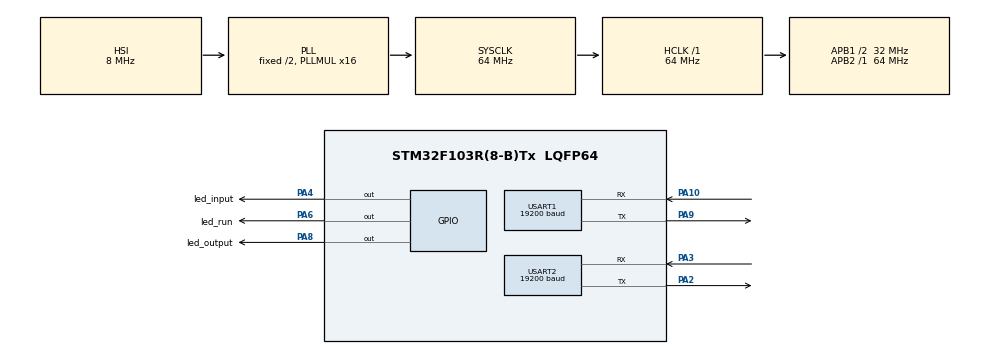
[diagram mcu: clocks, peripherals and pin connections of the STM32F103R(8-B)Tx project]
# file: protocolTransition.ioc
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Dma.Request0=USART1_RX
Dma.Request1=USART1_TX
Dma.Request2=USART2_RX
Dma.Request3=USART2_TX
Dma.USART1_RX.0.Direction=DMA_PERIPH_TO_MEMORY
Dma.USART1_RX.0.Instance=DMA1_Channel5
Dma.USART1_RX.0.MemDataAlignment=DMA_MDATAALIGN_BYTE
Dma.USART1_RX.0.MemInc=DMA_MINC_ENABLE
Dma.USART1_RX.0.Mode=DMA_NORMAL
Dma.USART1_RX.0.PeriphDataAlignment=DMA_PDATAALIGN_BYTE
Dma.USART1_RX.0.PeriphInc=DMA_PINC_DISABLE
Dma.USART1_RX.0.Priority=DMA_PRIORITY_LOW
Dma.USART1_TX.1.Direction=DMA_MEMORY_TO_PERIPH
Dma.USART1_TX.1.Instance=DMA1_Channel4
Dma.USART1_TX.1.MemDataAlignment=DMA_MDATAALIGN_BYTE
Dma.USART1_TX.1.MemInc=DMA_MINC_ENABLE
Dma.USART1_TX.1.Mode=DMA_NORMAL
Dma.USART1_TX.1.PeriphDataAlignment=DMA_PDATAALIGN_BYTE
Dma.USART1_TX.1.PeriphInc=DMA_PINC_DISABLE
Dma.USART1_TX.1.Priority=DMA_PRIORITY_LOW
Dma.USART2_RX.2.Direction=DMA_PERIPH_TO_MEMORY
Dma.USART2_RX.2.Instance=DMA1_Channel6
Dma.USART2_RX.2.MemDataAlignment=DMA_MDATAALIGN_BYTE
Dma.USART2_RX.2.MemInc=DMA_MINC_ENABLE
Dma.USART2_RX.2.Mode=DMA_NORMAL
Dma.USART2_RX.2.PeriphDataAlignment=DMA_PDATAALIGN_BYTE
Dma.USART2_RX.2.PeriphInc=DMA_PINC_DISABLE
Dma.USART2_RX.2.Priority=DMA_PRIORITY_LOW
Dma.USART2_TX.3.Direction=DMA_MEMORY_TO_PERIPH
Dma.USART2_TX.3.Instance=DMA1_Channel7
Dma.USART2_TX.3.MemDataAlignment=DMA_MDATAALIGN_BYTE
Dma.USART2_TX.3.MemInc=DMA_MINC_ENABLE
Dma.USART2_TX.3.Mode=DMA_NORMAL
Dma.USART2_TX.3.PeriphDataAlignment=DMA_PDATAALIGN_BYTE
Dma.USART2_TX.3.PeriphInc=DMA_PINC_DISABLE
Dma.USART2_TX.3.Priority=DMA_PRIORITY_LOW
Mcu.Family=STM32F1
Mcu.Name=STM32F103R(8-B)Tx
Mcu.Package=LQFP64
NVIC.DMA1_Channel4_IRQn=true\:0\:0\:false\:false\:true\:false
NVIC.DMA1_Channel5_IRQn=true\:0\:0\:false\:false\:true\:false
NVIC.DMA1_Channel6_IRQn=true\:0\:0\:false\:false\:true\:false
NVIC.DMA1_Channel7_IRQn=true\:0\:0\:false\:false\:true\:false
NVIC.PriorityGroup=NVIC_PRIORITYGROUP_4
NVIC.TIM3_IRQn=true\:0\:0\:false\:false\:true\:true
NVIC.USART1_IRQn=true\:0\:0\:false\:false\:true\:true
NVIC.USART2_IRQn=true\:0\:0\:false\:false\:true\:true
PA10.Mode=Asynchronous
PA10.Signal=USART1_RX
PA13.Mode=Serial_Wire
PA13.Signal=SYS_JTMS-SWDIO
PA14.Mode=Serial_Wire
PA14.Signal=SYS_JTCK-SWCLK
PA2.Mode=Asynchronous
PA2.Signal=USART2_TX
PA3.Mode=Asynchronous
PA3.Signal=USART2_RX
PA4.GPIO_Label=led_input
PA4.Signal=GPIO_Output
PA6.GPIO_Label=led_run
PA6.Signal=GPIO_Output
PA8.GPIO_Label=led_output
PA8.Signal=GPIO_Output
PA9.Mode=Asynchronous
PA9.Signal=USART1_TX
ProjectManager.HeapSize=0x200
ProjectManager.StackSize=0x400
ProjectManager.TargetToolchain=Other Toolchains (GPDSC)
RCC.AHBFreq_Value=64000000
RCC.APB1CLKDivider=RCC_HCLK_DIV2
RCC.APB1Freq_Value=32000000
RCC.APB1TimFreq_Value=64000000
RCC.APB2Freq_Value=64000000
RCC.APB2TimFreq_Value=64000000
RCC.HCLKFreq_Value=64000000
RCC.PLLMUL=RCC_PLL_MUL16
RCC.SYSCLKFreq_VALUE=64000000
RCC.SYSCLKSource=RCC_SYSCLKSOURCE_PLLCLK
RCC.USBFreq_Value=64000000
TIM3.Period=1000-1
TIM3.Prescaler=6400-1
USART1.BaudRate=19200
USART1.VirtualMode=VM_ASYNC
USART2.BaudRate=19200
USART2.VirtualMode=VM_ASYNC
VP_TIM3_VS_ClockSourceINT.Mode=Internal
board=protocolTransition

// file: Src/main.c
/**
  ******************************************************************************
  * @file           : main.c
  * @brief          : Main program body
  ******************************************************************************
  ** This notice applies to any and all portions of this file
  * that are not between comment pairs USER CODE BEGIN and
  * USER CODE END. Other portions of this file, whether
  * inserted by the user or by software development tools
  * are owned by their respective copyright owners.
  *
  * COPYRIGHT(c) 2018 STMicroelectronics
  *
  * Redistribution and use in source and binary forms, with or without modification,
  * are permitted provided that the following conditions are met:
  *   1. Redistributions of source code must retain the above copyright notice,
  *      this list of conditions and the following disclaimer.
  *   2. Redistributions in binary form must reproduce the above copyright notice,
  *      this list of conditions and the following disclaimer in the documentation
  *      and/or other materials provided with the distribution.
  *   3. Neither the name of STMicroelectronics nor the names of its contributors
  *      may be used to endorse or promote products derived from this software
  *      without specific prior written permission.
  *
  * THIS SOFTWARE IS PROVIDED BY THE COPYRIGHT HOLDERS AND CONTRIBUTORS "AS IS"
  * AND ANY EXPRESS OR IMPLIED WARRANTIES, INCLUDING, BUT NOT LIMITED TO, THE
  * IMPLIED WARRANTIES OF MERCHANTABILITY AND FITNESS FOR A PARTICULAR PURPOSE ARE
  * DISCLAIMED. IN NO EVENT SHALL THE COPYRIGHT HOLDER OR CONTRIBUTORS BE LIABLE
  * FOR ANY DIRECT, INDIRECT, INCIDENTAL, SPECIAL, EXEMPLARY, OR CONSEQUENTIAL
  * DAMAGES (INCLUDING, BUT NOT LIMITED TO, PROCUREMENT OF SUBSTITUTE GOODS OR
  * SERVICES; LOSS OF USE, DATA, OR PROFITS; OR BUSINESS INTERRUPTION) HOWEVER
  * CAUSED AND ON ANY THEORY OF LIABILITY, WHETHER IN CONTRACT, STRICT LIABILITY,
  * OR TORT (INCLUDING NEGLIGENCE OR OTHERWISE) ARISING IN ANY WAY OUT OF THE USE
  * OF THIS SOFTWARE, EVEN IF ADVISED OF THE POSSIBILITY OF SUCH DAMAGE.
  *
  ******************************************************************************
  */
#include "main.h"
#include "stm32f1xx_hal.h"
#include "dma.h"
#include "tim.h"
#include "usart.h"
#include "gpio.h"

/* USER CODE BEGIN PV */
/* Private variables ---------------------------------------------------------*/

/* USER CODE END PV */

void SystemClock_Config(void);

/* USER CODE BEGIN PFP */
/* Private function prototypes -----------------------------------------------*/

/* USER CODE END PFP */

int main(void)
{

  /* MCU Configuration----------------------------------------------------------*/

  /* Reset of all peripherals, Initializes the Flash interface and the Systick. */
  HAL_Init();

  /* Configure the system clock */
  SystemClock_Config();

  /* Initialize all configured peripherals */
  MX_GPIO_Init();
  MX_DMA_Init();
  MX_USART2_UART_Init();
  MX_USART1_UART_Init();
  MX_TIM3_Init();
  /* USER CODE BEGIN 2 */
  HAL_TIM_Base_Start_IT(&htim3);
  __HAL_UART_ENABLE_IT(&huart1, UART_IT_IDLE);    //使能空闲中断
  __HAL_UART_ENABLE_IT(&huart2, UART_IT_IDLE);

  /* USER CODE END 2 */

  /* Infinite loop */
  while (1)
  {

  /* USER CODE BEGIN 3 */

	  modbusMasterScan();

  }
  /* USER CODE END 3 */

}

void SystemClock_Config(void)
{

  RCC_OscInitTypeDef RCC_OscInitStruct;
  RCC_ClkInitTypeDef RCC_ClkInitStruct;

    /**Initializes the CPU, AHB and APB busses clocks
    */
  RCC_OscInitStruct.OscillatorType = RCC_OSCILLATORTYPE_HSI;
  RCC_OscInitStruct.HSIState = RCC_HSI_ON;
  RCC_OscInitStruct.HSICalibrationValue = 16;
  RCC_OscInitStruct.PLL.PLLState = RCC_PLL_ON;
  RCC_OscInitStruct.PLL.PLLSource = RCC_PLLSOURCE_HSI_DIV2;
  RCC_OscInitStruct.PLL.PLLMUL = RCC_PLL_MUL16;
  if (HAL_RCC_OscConfig(&RCC_OscInitStruct) != HAL_OK)
  {
    _Error_Handler(__FILE__, __LINE__);
  }

    /**Initializes the CPU, AHB and APB busses clocks
    */
  RCC_ClkInitStruct.ClockType = RCC_CLOCKTYPE_HCLK|RCC_CLOCKTYPE_SYSCLK
                              |RCC_CLOCKTYPE_PCLK1|RCC_CLOCKTYPE_PCLK2;
  RCC_ClkInitStruct.SYSCLKSource = RCC_SYSCLKSOURCE_PLLCLK;
  RCC_ClkInitStruct.AHBCLKDivider = RCC_SYSCLK_DIV1;
  RCC_ClkInitStruct.APB1CLKDivider = RCC_HCLK_DIV2;
  RCC_ClkInitStruct.APB2CLKDivider = RCC_HCLK_DIV1;

  if (HAL_RCC_ClockConfig(&RCC_ClkInitStruct, FLASH_LATENCY_2) != HAL_OK)
  {
    _Error_Handler(__FILE__, __LINE__);
  }

    /**Configure the Systick interrupt time
    */
  HAL_SYSTICK_Config(HAL_RCC_GetHCLKFreq()/1000);

    /**Configure the Systick
    */
  HAL_SYSTICK_CLKSourceConfig(SYSTICK_CLKSOURCE_HCLK);

  /* SysTick_IRQn interrupt configuration */
  HAL_NVIC_SetPriority(SysTick_IRQn, 0, 0);
}

void _Error_Handler(char *file, int line)
{
  while(1)
  {
  }
}

/************************ (C) COPYRIGHT STMicroelectronics *****END OF FILE****/
